# ATmega32U2 register map
Vendor: Atmel; File version: 1.0
CPU: other r0p0, little endian, no MPU, no FPU, 4 interrupt priority bits
Registers are 8-bit, read-write, reset 0x0 unless marked. A register's access mark holds for its fields unless they carry their own. Offsets are from the block's base; [hi:lo] are bit positions.

## FUSE — Fuses
Base 0x00000000
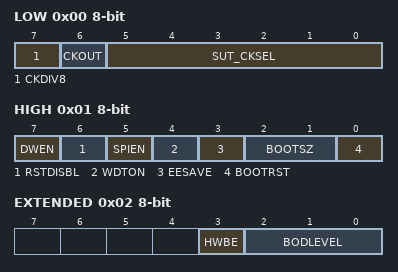
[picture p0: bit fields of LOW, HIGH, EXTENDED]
0x00 LOW
  [7] CKDIV8 — Divide clock by 8 internally
  [6] CKOUT — Clock output on PORTC7
  [5:0] SUT_CKSEL — Select Clock Source
    0=EXTCLK_6CK_0MS (Ext. Clock; Start-up time: 6 CK + 0 ms); 2=INTRCOSC_6CK_0MS (Int. RC Osc.; Start-up time: 6 CK + 0 ms); 4=EXTLOFXTAL_1KCK_0MS (Ext. Low-Freq. Crystal; Start-up time: 1K CK + 0 ms); 5=EXTLOFXTAL_32KCK_0MS (Ext. Low-Freq. Crystal; Start-up time: 32K CK + 0 ms); 6=EXTLOFXTAL_1KCK_0MS_INTCAP (Ext. Low-Freq. Crystal; Start-up time: 1K CK + 0 ms; Int. Cap.); 7=EXTLOFXTAL_32KCK_0MS_INTCAP (Ext. Low-Freq. Crystal; Start-up time: 32K CK + 0 ms; Int. Cap.); 8=EXTXOSC_0MHZ4_0MHZ9_258CK_4MS1 (Ext. Crystal Osc. 0.4-0.9 MHz; Start-up time: 258 CK + 4.1 ms); 9=EXTXOSC_0MHZ4_0MHZ9_1KCK_65MS (Ext. Crystal Osc. 0.4-0.9 MHz; Start-up time: 1K CK + 65 ms); 10=EXTXOSC_0MHZ9_3MHZ_258CK_4MS1 (Ext. Crystal Osc. 0.9-3.0 MHz; Start-up time: 258 CK + 4.1 ms); 11=EXTXOSC_0MHZ9_3MHZ_1KCK_65MS (Ext. Crystal Osc. 0.9-3.0 MHz; Start-up time: 1K CK + 65 ms); 12=EXTXOSC_3MHZ_8MHZ_258CK_4MS1 (Ext. Crystal Osc. 3.0-8.0 MHz; Start-up time: 258 CK + 4.1 ms); 13=EXTXOSC_3MHZ_8MHZ_1KCK_65MS (Ext. Crystal Osc. 3.0-8.0 MHz; Start-up time: 1K CK + 65 ms); 14=EXTXOSC_8MHZ_XX_258CK_4MS1 (Ext. Crystal Osc. 8.0- MHz; Start-up time: 258 CK + 4.1 ms); 15=EXTXOSC_8MHZ_XX_1KCK_65MS (Ext. Crystal Osc. 8.0- MHz; Start-up time: 1K CK + 65 ms); 16=EXTCLK_6CK_4MS1 (Ext. Clock; Start-up time: 6 CK + 4.1 ms); 18=INTRCOSC_6CK_4MS1 (Int. RC Osc.; Start-up time: 6 CK + 4.1 ms); 20=EXTLOFXTAL_1KCK_4MS1 (Ext. Low-Freq. Crystal; Start-up time: 1K CK + 4.1 ms); 21=EXTLOFXTAL_32KCK_4MS1 (Ext. Low-Freq. Crystal; Start-up time: 32K CK + 4.1 ms); 22=EXTLOFXTAL_1KCK_4MS1_INTCAP (Ext. Low-Freq. Crystal; Start-up time: 1K CK + 4.1 ms; Int. Cap.); 23=EXTLOFXTAL_32KCK_4MS1_INTCAP (Ext. Low-Freq. Crystal; Start-up time: 32K CK + 4.1 ms; Int. Cap.); 24=EXTXOSC_0MHZ4_0MHZ9_258CK_65MS (Ext. Crystal Osc. 0.4-0.9 MHz; Start-up time: 258 CK + 65 ms); 25=EXTXOSC_0MHZ4_0MHZ9_16KCK_0MS (Ext. Crystal Osc. 0.4-0.9 MHz; Start-up time: 16K CK + 0 ms); 26=EXTXOSC_0MHZ9_3MHZ_258CK_65MS (Ext. Crystal Osc. 0.9-3.0 MHz; Start-up time: 258 CK + 65 ms); 27=EXTXOSC_0MHZ9_3MHZ_16KCK_0MS (Ext. Crystal Osc. 0.9-3.0 MHz; Start-up time: 16K CK + 0 ms); 28=EXTXOSC_3MHZ_8MHZ_258CK_65MS (Ext. Crystal Osc. 3.0-8.0 MHz; Start-up time: 258 CK + 65 ms); 29=EXTXOSC_3MHZ_8MHZ_16KCK_0MS (Ext. Crystal Osc. 3.0-8.0 MHz; Start-up time: 16K CK + 0 ms); 30=EXTXOSC_8MHZ_XX_258CK_65MS (Ext. Crystal Osc. 8.0- MHz; Start-up time: 258 CK + 65 ms); 31=EXTXOSC_8MHZ_XX_16KCK_0MS (Ext. Crystal Osc. 8.0- MHz; Start-up time: 16K CK + 0 ms); 32=EXTCLK_6CK_65MS (Ext. Clock; Start-up time: 6 CK + 65 ms); 34=INTRCOSC_6CK_65MS (Int. RC Osc.; Start-up time: 6 CK + 65 ms); 36=EXTLOFXTAL_1KCK_65MS (Ext. Low-Freq. Crystal; Start-up time: 1K CK + 65 ms); 37=EXTLOFXTAL_32KCK_65MS (Ext. Low-Freq. Crystal; Start-up time: 32K CK + 65 ms); 38=EXTLOFXTAL_1KCK_65MS_INTCAP (Ext. Low-Freq. Crystal; Start-up time: 1K CK + 65 ms; Int. Cap.); 39=EXTLOFXTAL_32KCK_65MS_INTCAP (Ext. Low-Freq. Crystal; Start-up time: 32K CK + 65 ms; Int. Cap.); 40=EXTXOSC_0MHZ4_0MHZ9_1KCK_0MS (Ext. Crystal Osc. 0.4-0.9 MHz; Start-up time: 1K CK + 0 ms); 41=EXTXOSC_0MHZ4_0MHZ9_16KCK_4MS1 (Ext. Crystal Osc. 0.4-0.9 MHz; Start-up time: 16K CK + 4.1 ms); 42=EXTXOSC_0MHZ9_3MHZ_1KCK_0MS (Ext. Crystal Osc. 0.9-3.0 MHz; Start-up time: 1K CK + 0 ms); 43=EXTXOSC_0MHZ9_3MHZ_16KCK_4MS1 (Ext. Crystal Osc. 0.9-3.0 MHz; Start-up time: 16K CK + 4.1 ms); 44=EXTXOSC_3MHZ_8MHZ_1KCK_0MS (Ext. Crystal Osc. 3.0-8.0 MHz; Start-up time: 1K CK + 0 ms); 45=EXTXOSC_3MHZ_8MHZ_16KCK_4MS1 (Ext. Crystal Osc. 3.0-8.0 MHz; Start-up time: 16K CK + 4.1 ms); 46=EXTXOSC_8MHZ_XX_1KCK_0MS (Ext. Crystal Osc. 8.0- MHz; Start-up time: 1K CK + 0 ms); 47=EXTXOSC_8MHZ_XX_16KCK_4MS1 (Ext. Crystal Osc. 8.0- MHz; Start-up time: 16K CK + 4.1 ms); 56=EXTXOSC_0MHZ4_0MHZ9_1KCK_4MS1 (Ext. Crystal Osc. 0.4-0.9 MHz; Start-up time: 1K CK + 4.1 ms); 57=EXTXOSC_0MHZ4_0MHZ9_16KCK_65MS (Ext. Crystal Osc. 0.4-0.9 MHz; Start-up time: 16K CK + 65 ms); 58=EXTXOSC_0MHZ9_3MHZ_1KCK_4MS1 (Ext. Crystal Osc. 0.9-3.0 MHz; Start-up time: 1K CK + 4.1 ms); 59=EXTXOSC_0MHZ9_3MHZ_16KCK_65MS (Ext. Crystal Osc. 0.9-3.0 MHz; Start-up time: 16K CK + 65 ms); 60=EXTXOSC_3MHZ_8MHZ_1KCK_4MS1 (Ext. Crystal Osc. 3.0-8.0 MHz; Start-up time: 1K CK + 4.1 ms); 61=EXTXOSC_3MHZ_8MHZ_16KCK_65MS (Ext. Crystal Osc. 3.0-8.0 MHz; Start-up time: 16K CK + 65 ms); 62=EXTXOSC_8MHZ_XX_1KCK_4MS1 (Ext. Crystal Osc. 8.0- MHz; Start-up time: 1K CK + 4.1 ms); 63=EXTXOSC_8MHZ_XX_16KCK_65MS (Ext. Crystal Osc. 8.0- MHz; Start-up time: 16K CK + 65 ms)
0x01 HIGH
  [7] DWEN — Debug Wire enable
  [6] RSTDISBL — Reset Disabled (Enable PC6 as i/o pin)
  [5] SPIEN — Serial program downloading (SPI) enabled
  [4] WDTON — Watchdog timer always on
  [3] EESAVE — Preserve EEPROM through the Chip Erase cycle
  [2:1] BOOTSZ — Select Boot Size
    0=2048W_3800 (Boot Flash size=2048 words start address=$3800); 1=1024W_3C00 (Boot Flash size=1024 words start address=$3C00); 2=512W_3E00 (Boot Flash size=512 words start address=$3E00); 3=256W_3F00 (Boot Flash size=256 words start address=$3F00)
  [0] BOOTRST — Boot Reset vector Enabled
0x02 EXTENDED
  [3] HWBE — Hardware Boot Enable
  [2:0] BODLEVEL — Brown-out Detector trigger level
    0=4V3 (Brown-out detection level at VCC=4.3 V); 1=4V0 (Brown-out detection level at VCC=4.0 V); 2=3V6 (Brown-out detection level at VCC=3.6 V); 3=3V5 (Brown-out detection level at VCC=3.5 V); 4=3V0 (Brown-out detection level at VCC=3.0 V); 5=2V9 (Brown-out detection level at VCC=2.9 V); 6=2V7 (Brown-out detection level at VCC=2.7 V); 7=DISABLED (Brown-out detection disabled)
